# DA14680 register map
Vendor: Dialog; Series: DA14680; File version: 1.2
CPU: CM0 r1p0, little endian, MPU, FPU, 3 interrupt priority bits
Registers are 16-bit, read-write, reset 0x0 unless marked. A register's access mark holds for its fields unless they carry their own. Offsets are from the block's base; [hi:lo] are bit positions.

## SPI2 — SPI2 registers
Base 0x50001300
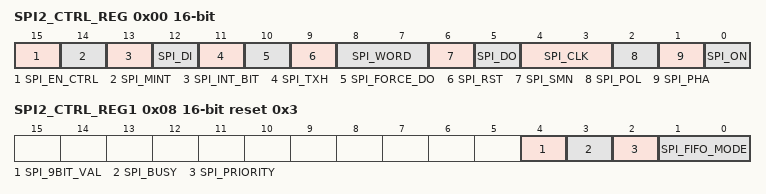
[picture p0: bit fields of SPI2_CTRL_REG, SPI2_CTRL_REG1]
0x00 SPI2_CTRL_REG — SPI control register 0
  [15] SPI_EN_CTRL — 0 = SPI_EN pin disabled in slave mode. Pin SPI_EN is don't care. 1 = SPI_EN pin enabled in slave mode.
  [14] SPI_MINT — 0 = Disable SPI_INT_BIT to ICU 1 = Enable SPI_INT_BIT to ICU. Note that the SPI_INT interrupt is shared with AD_INT interrupt
  [13] SPI_INT_BIT ro — 0 = RX Register or FIFO is empty. 1 = SPI interrupt. Data has been transmitted and receivedMust be reset by SW by writing to SPI_CLEAR_INT_REG.
  [12] SPI_DI ro — Returns the actual value of pin SPI_DIN (delayed with two internal SPI clock cycles)
  [11] SPI_TXH ro — 0 = TX-FIFO is not full, data can be written. 1 = TX-FIFO is full, data can not be written.
  [10] SPI_FORCE_DO — 0 = normal operation 1 = Force SPIDO output level to value of SPI_DO.
  [9] SPI_RST — 0 = normal operation 1 = Reset SPI. Same function as SPI_ON except that internal clock remain active.
  [8:7] SPI_WORD — 00 = 8 bits mode, only SPI_RX_TX_REG0 used 01 = 16 bit mode, only SPI_RX_TX_REG0 used 10 = 32 bits mode, SPI_RX_TX_REG0 & SPI_RX_TX_REG1 used 11 = 9 bits mode. Only valid in master mode.
  [6] SPI_SMN — Master/slave mode 0 = Master, 1 = Slave(SPI1 only)
  [5] SPI_DO — Pin SPI_DO output level when SPI is idle or when SPI_FORCE_DO=1
  [4:3] SPI_CLK — Select SPI_CLK clock output frequency in master mode: 00 = SPI_CLK / 8 01 = SPI_CLK / 4 10 = SPI_CLK / 2 11 = SPI_CLK / 14
  [2] SPI_POL — Select SPI_CLK polarity. 0 = SPI_CLK is initially low. 1 = SPI_CLK is initially high.
  [1] SPI_PHA — Select SPI_CLK phase. See functional timing diagrams in SPI chapter
  [0] SPI_ON — 0 = SPI Module switched off (power saving). Everything is reset except SPI_CTRL_REG0 and SPI_CTRL_REG1. When this bit is cleared the SPI will remain active in master mode until the shift register and holding register are both empty. 1 = SPI Module switched on. Should only be set after all control bits have their desired values. So two writes are needed!
0x02 SPI2_RX_TX_REG0 — SPI RX/TX register0
  [15:0] SPI_DATA0 wo — Write: SPI_TX_REG0 output register 0 (TX-FIFO) Read: SPI_RX_REG0 input register 0 (RX-FIFO) In 8 or 9 bits mode bits 15 to 8 are not used, they contain old data.
0x04 SPI2_RX_TX_REG1 — SPI RX/TX register1
  [15:0] SPI_DATA1 wo — Write: SPI_TX_REG1 output register 1 (MSB's of TX-FIFO) Read: SPI_RX_REG1 input register 1 (MSB's of RX-FIFO) In 8 or 9 or 16 bits mode bits this register is not used.
0x06 SPI2_CLEAR_INT_REG — SPI clear interrupt register
  [15:0] SPI_CLEAR_INT wo — Writing any value to this register will clear the SPI_CTRL_REG[SPI_INT_BIT] Reading returns 0.
0x08 SPI2_CTRL_REG1 reset 0x3 — SPI control register 1
  [4] SPI_9BIT_VAL — Determines the value of the first bit in 9 bits SPI mode.
  [3] SPI_BUSY ro — 0 = The SPI is not busy with a transfer. This means that either no TX-data is available or that the transfers have been suspended due to a full RX-FIFO. The SPIx_CTRL_REG0[SPI_INT_BIT] can be used to distinguish between these situations. 1 = The SPI is busy with a transfer.
  [2] SPI_PRIORITY — 0 = The SPI has low priority, the DMA request signals are reset after the corresponding acknowledge. 1 = The SPI has high priority, DMA request signals remain active until the FIFOS are filled/emptied, so the DMA holds the AHB bus.
  [1:0] SPI_FIFO_MODE — 0: TX-FIFO and RX-FIFO used (Bidirectional mode). 1: RX-FIFO used (Read Only Mode) TX-FIFO single depth, no flow control 2: TX-FIFO used (Write Only Mode), RX-FIFO single depth, no flow control 3: No FIFOs used (backwards compatible mode)

## TIMER1 — TIMER1 registers
Base 0x50000200
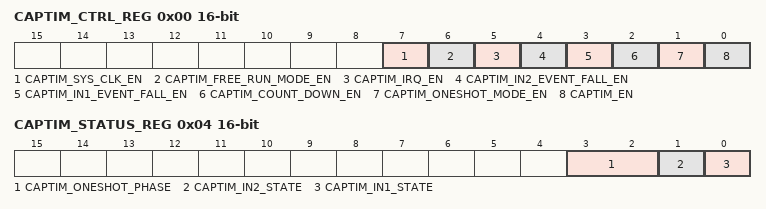
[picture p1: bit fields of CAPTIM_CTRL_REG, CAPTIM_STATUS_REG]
0x00 CAPTIM_CTRL_REG — Capture Timer control register
  [7] CAPTIM_SYS_CLK_EN — '1' When Capture Timer use the system clock else use the clock 32KHz
  [6] CAPTIM_FREE_RUN_MODE_EN — Only when timer counts up, if it is '1' timer does not zero when reaches to reload value. it is zero only when it has the max value.
  [5] CAPTIM_IRQ_EN — '1' When Capture timer IRQ unmask, '0' masked
  [4] CAPTIM_IN2_EVENT_FALL_EN — '1' When Input1 event type is falling edge, '0' rising edge
  [3] CAPTIM_IN1_EVENT_FALL_EN — '1' When Input2 event type is falling edge, '0' rising edge
  [2] CAPTIM_COUNT_DOWN_EN — '1' when timer counts down, '0' count up
  [1] CAPTIM_ONESHOT_MODE_EN — '1' Capture Timer in OneShot mode, '0' Capture/Timer mode
  [0] CAPTIM_EN — '1' Capture Timer enabled, else disabled
0x02 CAPTIM_TIMER_VAL_REG — Capture Timer counter value
  [15:0] CAPTIM_TIMER_VALUE ro — Gives the current timer value
0x04 CAPTIM_STATUS_REG — Capture Timer status register
  [3:2] CAPTIM_ONESHOT_PHASE ro — 0 : Wait for event, 1 : Delay phase, 2 : Start Shot, 3 : Shot phase
  [1] CAPTIM_IN2_STATE ro — Gives the logic level of the IN1
  [0] CAPTIM_IN1_STATE ro — Gives the logic level of the IN2
0x06 CAPTIM_GPIO1_CONF_REG — Capture Timer gpio1 selection
  [5:0] CAPTIM_GPIO1_CONF — Select one of the 37 GPIOs as IN1, Valid value 0-37. 1 for P00 .. 37 for P47. When 0 Disable input
0x08 CAPTIM_GPIO2_CONF_REG — Capture Timer gpio2 selection
  [5:0] CAPTIM_GPIO2_CONF — Select one of the 37 GPIOs as IN2, Valid value 0-37. 1 for P00 .. 37 for P47. When 0 Disable input
0x0A CAPTIM_RELOAD_REG — Capture Timer reload value and Delay in shot mode
  [15:0] CAPTIM_RELOAD — Reload or max value in timer mode, Delay phase duration in oneshot mode. Actual delay is the register value plus synchronization time (3 clock cycles)
0x0C CAPTIM_SHOTWIDTH_REG — Capture Timer Shot duration in shot mode
  [15:0] CAPTIM_SHOTWIDTH — Shot phase duration in oneshot mode
0x0E CAPTIM_PRESCALER_REG — Capture Timer prescaler value
  [15:0] CAPTIM_PRESCALER — Define the timer count frequncy. Freq = Freq_clock / (value+1)
0x10 CAPTIM_CAPTURE_GPIO1_REG — Capture Timer value for event on GPIO1
  [15:0] CAPTIM_CAPTURE_GPIO1 ro — Gives the Capture time for event on GPIO1
0x12 CAPTIM_CAPTURE_GPIO2_REG — Capture Timer value for event on GPIO2
  [15:0] CAPTIM_CAPTURE_GPIO2 ro — Gives the Capture time for event on GPIO2
0x14 CAPTIM_PRESCALER_VAL_REG — Capture Timer interrupt status register
  [15:0] CAPTIM_PRESCALER_VAL ro — Gives the current prescaler value
0x16 CAPTIM_PWM_FREQ_REG — Capture Timer pwm frequency register. PWM5 period is defined by the reference clock frequency multiplied by this value.
  [15:0] CAPTIM_PWM_FREQ — Define the PWM frequency. = prescaler frequency / (value+1)
0x18 CAPTIM_PWM_DC_REG — Capture Timer pwm dc register
  [15:0] CAPTIM_PWM_DC — Define the PWM duty cyucle = pwm_dc / ( pwm_freq+1)
